# FT32F0xx register map
File version: 1.0
Registers are 32-bit, read-write, reset 0x0 unless marked. A register's access mark holds for its fields unless they carry their own. Offsets are from the block's base; [hi:lo] are bit positions.

## TSC — Touch sensing controller
Base 0x40024000
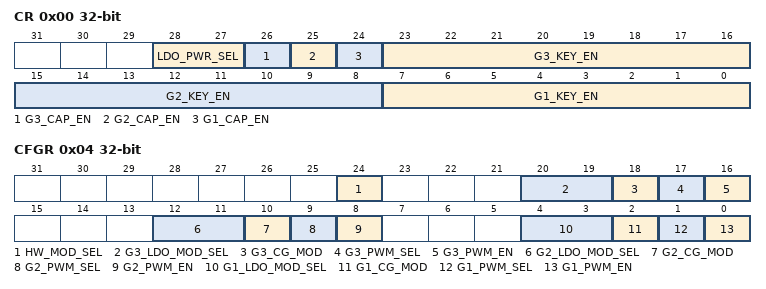
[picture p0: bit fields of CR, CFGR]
0x00 CR — control register
  [28:27] LDO_PWR_SEL — Charge transfer pulse high
  [26] G3_CAP_EN — Charge transfer pulse low
  [25] G2_CAP_EN — Spread spectrum deviation
  [24] G1_CAP_EN — Spread spectrum enable
  [23:16] G3_KEY_EN — Spread spectrum prescaler
  [15:8] G2_KEY_EN — pulse generator prescaler
  [7:0] G1_KEY_EN — Max count value
0x04 CFGR — TSC configuration register
  [24] HW_MOD_SEL — Max count error interrupt enable
  [20:19] G3_LDO_MOD_SEL — End of acquisition interrupt enable
  [18] G3_CG_MOD — End of acquisition interrupt enable
  [17] G3_PWM_SEL — End of acquisition interrupt enable
  [16] G3_PWM_EN — End of acquisition interrupt enable
  [12:11] G2_LDO_MOD_SEL — End of acquisition interrupt enable
  [10] G2_CG_MOD — End of acquisition interrupt enable
  [9] G2_PWM_SEL — End of acquisition interrupt enable
  [8] G2_PWM_EN — End of acquisition interrupt enable
  [4:3] G1_LDO_MOD_SEL — End of acquisition interrupt enable
  [2] G1_CG_MOD — End of acquisition interrupt enable
  [1] G1_PWM_SEL — End of acquisition interrupt enable
  [0] G1_PWM_EN — End of acquisition interrupt enable

## Flash
Base 0x40022000
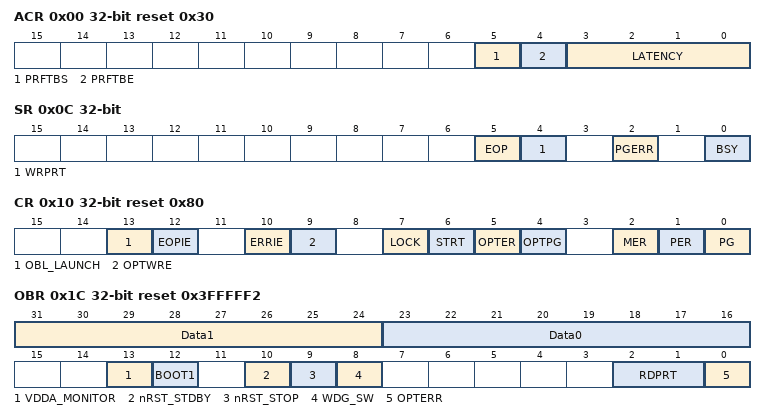
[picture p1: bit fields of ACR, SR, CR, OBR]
0x00 ACR access per field reset 0x30 — Flash access control register
  [5] PRFTBS ro, [4] PRFTBE rw, [3:0] LATENCY rw
0x04 KEYR wo — Flash key register
  [31:0] FKEYR — Flash Key
0x08 OPTKEYR wo — Flash option key register
  [31:0] OPTKEYR — Option byte key
0x0C SR access per field — Flash status register
  [5] EOP rw — End of operation
  [4] WRPRT rw — Write protection error
  [2] PGERR rw — Programming error
  [0] BSY ro — Busy
0x10 CR reset 0x80 — Flash control register
  [13] OBL_LAUNCH — Force option byte loading
  [12] EOPIE — End of operation interrupt enable
  [10] ERRIE — Error interrupt enable
  [9] OPTWRE — Option bytes write enable
  [7] LOCK
  [6] STRT — Start
  [5] OPTER — Option byte erase
  [4] OPTPG — Option byte programming
  [2] MER — Mass erase
  [1] PER — Page erase
  [0] PG — Programming
0x14 AR wo — Flash address register
  [31:0] FAR — Flash address
0x1C OBR ro reset 0x3FFFFF2 — Option byte register
  [31:24] Data1
  [23:16] Data0
  [13] VDDA_MONITOR
  [12] BOOT1
  [10] nRST_STDBY
  [9] nRST_STOP
  [8] WDG_SW
  [2:1] RDPRT — Level protection status
  [0] OPTERR — Option byte error
0x20 WRPR ro reset 0xFFFFFFFF — Write protection register
  [31:0] WRP — Write protect

## OP — operational support
Base 0x40010030
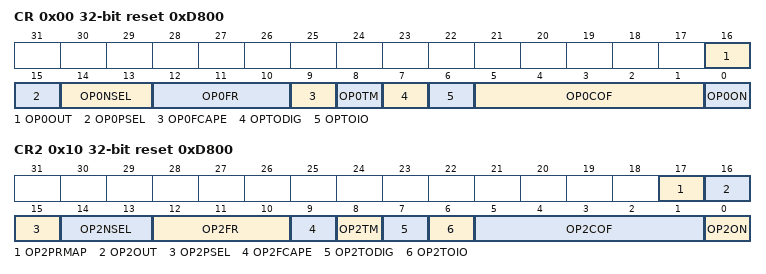
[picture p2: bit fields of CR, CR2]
0x00 CR reset 0xD800
  [16] OP0OUT — Revision Identifier
  [15] OP0PSEL — Revision Identifier
  [14:13] OP0NSEL — Revision Identifier
  [12:10] OP0FR — Revision Identifier
  [9] OP0FCAPE — Revision Identifier
  [8] OP0TM — Revision Identifier
  [7] OPTODIG — Revision Identifier
  [6] OPTOIO — Revision Identifier
  [5:1] OP0COF — Division Identifier
  [0] OP0ON — Device Identifier
0x10 CR2 reset 0xD800
  [17] OP2PRMAP — Revision Identifier
  [16] OP2OUT — Revision Identifier
  [15] OP2PSEL — Revision Identifier
  [14:13] OP2NSEL — Revision Identifier
  [12:10] OP2FR — Revision Identifier
  [9] OP2FCAPE — Revision Identifier
  [8] OP2TM — Revision Identifier
  [7] OP2TODIG — Revision Identifier
  [6] OP2TOIO — Revision Identifier
  [5:1] OP2COF — Division Identifier
  [0] OP2ON — Device Identifier

## DEBUG — Debug support
Base 0x40015800
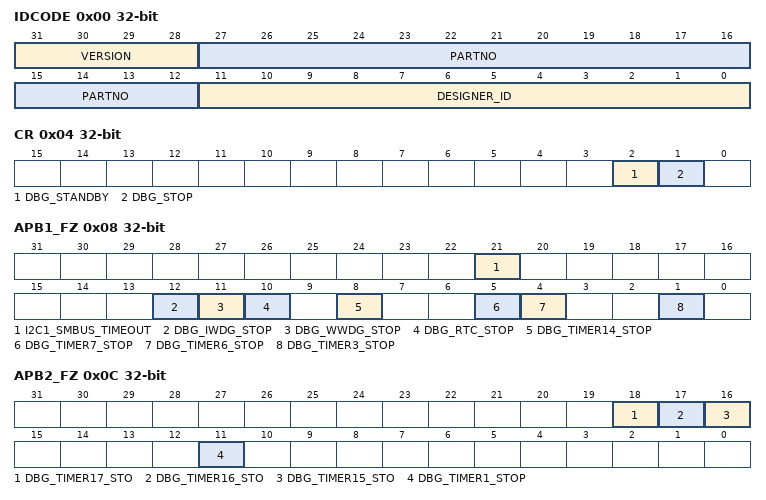
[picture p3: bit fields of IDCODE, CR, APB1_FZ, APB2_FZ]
0x00 IDCODE ro — MCU Device ID Code Register
  [31:28] VERSION — Revision Identifier
  [27:12] PARTNO — Division Identifier
  [11:0] DESIGNER_ID — Device Identifier
0x04 CR — Debug MCU Configuration Register
  [2] DBG_STANDBY — Debug Standby Mode
  [1] DBG_STOP — Debug Stop Mode
0x08 APB1_FZ — APB1 Freeze Register
  [21] I2C1_SMBUS_TIMEOUT — SMBUS timeout mode stopped when Core is halted
  [12] DBG_IWDG_STOP — Debug Independent Wachdog stopped when Core is halted
  [11] DBG_WWDG_STOP — Debug Window Wachdog stopped when Core is halted
  [10] DBG_RTC_STOP — Debug RTC stopped when Core is halted
  [8] DBG_TIMER14_STOP — Debug Timer 14 stopped when Core is halted
  [5] DBG_TIMER7_STOP — Debug Timer 7 stopped when Core is halted
  [4] DBG_TIMER6_STOP — Debug Timer 6 stopped when Core is halted
  [1] DBG_TIMER3_STOP — Debug Timer 3 stopped when Core is halted
0x0C APB2_FZ — APB2 Freeze Register
  [18] DBG_TIMER17_STO — Debug Timer 17 stopped when Core is halted
  [17] DBG_TIMER16_STO — Debug Timer 16 stopped when Core is halted
  [16] DBG_TIMER15_STO — Debug Timer 15 stopped when Core is halted
  [11] DBG_TIMER1_STOP — Debug Timer 1 stopped when Core is halted
